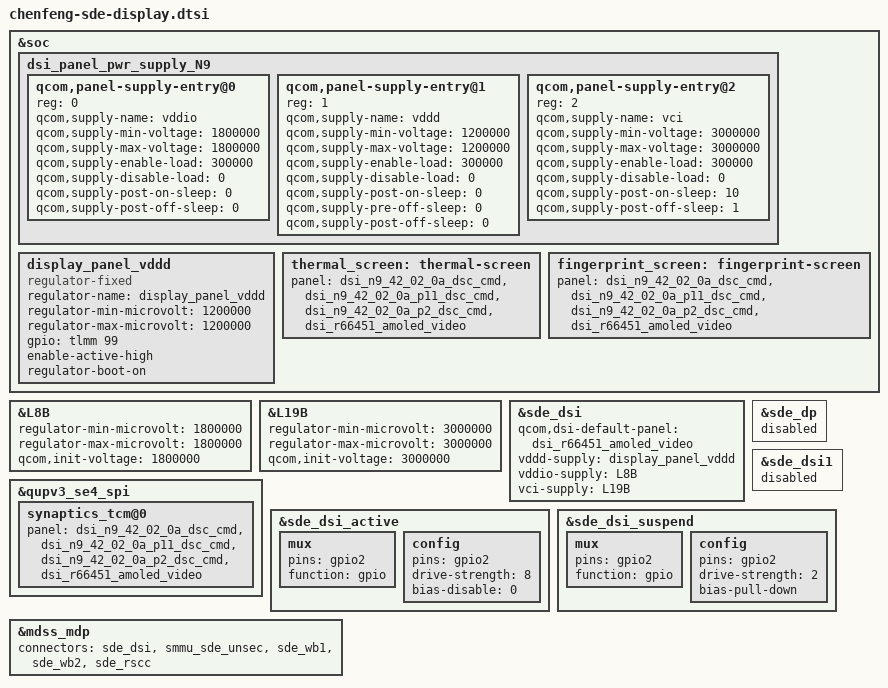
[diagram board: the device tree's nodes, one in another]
#include "cliffs-sde-display-mtp.dtsi"
#include "dsi-panel-n9-42-02-0a-dsc-cmd.dtsi"
#include "dsi-panel-n9-42-02-0a-p11-dsc-cmd.dtsi"
#include "dsi-panel-n9-42-02-0a-p2-dsc-cmd.dtsi"
#include "dsi-panel-r66451-dsc-fhd-plus-video.dtsi"

&soc {
	dsi_panel_pwr_supply_N9: dsi_panel_pwr_supply_N9 {
		qcom,panel-supply-entry@0 {
			reg = <0>;
			qcom,supply-name = "vddio";
			qcom,supply-min-voltage = <1800000>;
			qcom,supply-max-voltage = <1800000>;
			qcom,supply-enable-load = <300000>;
			qcom,supply-disable-load = <0>;
			qcom,supply-post-on-sleep = <0>;
			qcom,supply-post-off-sleep = <0>;
		};
		qcom,panel-supply-entry@1 {
			reg = <1>;
			qcom,supply-name = "vddd";
			qcom,supply-min-voltage = <1200000>;
			qcom,supply-max-voltage = <1200000>;
			qcom,supply-enable-load = <300000>;
			qcom,supply-disable-load = <0>;
			qcom,supply-post-on-sleep = <0>;
			qcom,supply-pre-off-sleep = <0>;
			qcom,supply-post-off-sleep = <0>;
		};
		qcom,panel-supply-entry@2 {
			reg = <2>;
			qcom,supply-name = "vci";
			qcom,supply-min-voltage = <3000000>;
			qcom,supply-max-voltage = <3000000>;
			qcom,supply-enable-load = <300000>;
			qcom,supply-disable-load = <0>;
			qcom,supply-post-on-sleep = <10>;
			qcom,supply-post-off-sleep = <1>;
		};
	};
};

&soc {
	display_panel_vddd: display_panel_vddd {
		compatible = "regulator-fixed";
		regulator-name = "display_panel_vddd";
		regulator-min-microvolt = <1200000>;
		regulator-max-microvolt = <1200000>;
		gpio = <&tlmm 99 0>;
		enable-active-high;
		regulator-boot-on;
	};
};

&L8B {
	regulator-min-microvolt = <1800000>;
	regulator-max-microvolt = <1800000>;
	qcom,init-voltage = <1800000>;
};

&L19B {
	regulator-min-microvolt = <3000000>;
	regulator-max-microvolt = <3000000>;
	qcom,init-voltage = <3000000>;
};

&sde_dsi {
	qcom,dsi-default-panel = <&dsi_r66451_amoled_video>;
	vddd-supply = <&display_panel_vddd>;
	vddio-supply = <&L8B>;
	vci-supply = <&L19B>;
};

&sde_dp {
	status = "ok";
};

&soc {
	thermal_screen: thermal-screen {
		panel = <&dsi_n9_42_02_0a_dsc_cmd
			&dsi_n9_42_02_0a_p11_dsc_cmd
			&dsi_n9_42_02_0a_p2_dsc_cmd
			&dsi_r66451_amoled_video>;
	};
	fingerprint_screen: fingerprint-screen {
		panel = <&dsi_n9_42_02_0a_dsc_cmd
			&dsi_n9_42_02_0a_p11_dsc_cmd
			&dsi_n9_42_02_0a_p2_dsc_cmd
			&dsi_r66451_amoled_video>;
	};
};
&qupv3_se4_spi {
	synaptics_tcm@0 {
		panel = <&dsi_n9_42_02_0a_dsc_cmd
			&dsi_n9_42_02_0a_p11_dsc_cmd
			&dsi_n9_42_02_0a_p2_dsc_cmd
			&dsi_r66451_amoled_video>;
	};
};
&sde_dsi1 {
	status = "disabled";
};
&sde_dsi_active {
	mux {
		pins = "gpio2";
		function = "gpio";
	};

	config {
		pins = "gpio2";
		drive-strength = <8>;   /* 8 mA */
		bias-disable = <0>;   /* no pull */
	};
};

&sde_dsi_suspend {
	mux {
		pins = "gpio2";
		function = "gpio";
	};

	config {
		pins = "gpio2";
		drive-strength = <2>;   /* 2 mA */
		bias-pull-down;         /* PULL DOWN */
	};
};

&sde_dp{
	status = "disable";
};

&mdss_mdp {
	connectors = <&sde_dsi &smmu_sde_unsec &sde_wb1 &sde_wb2 &sde_rscc>;
};
